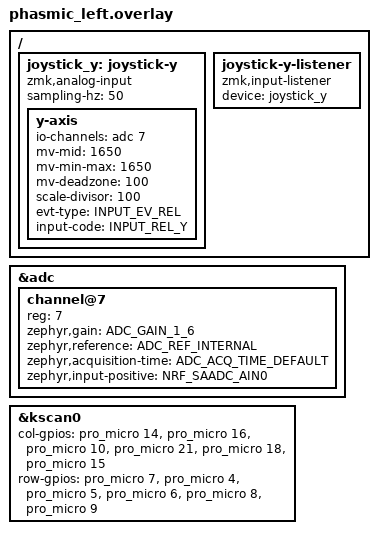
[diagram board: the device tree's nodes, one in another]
/*
 * Copyright (c) 2020 Ryan Cross
 *
 * SPDX-License-Identifier: MIT
 */

#include <zephyr/dt-bindings/adc/adc.h>
#include <zephyr/dt-bindings/adc/nrf-adc.h>
#include <zephyr/dt-bindings/input/input-event-codes.h>
#include "phasmic.dtsi"

&adc {
    #address-cells = <1>;
    #size-cells = <0>;

    channel@7 {
        // D19 (P0.02 / AIN0). ADC channel 0 is used for battery sensing.
        reg = <7>;
        zephyr,gain = "ADC_GAIN_1_6";
        zephyr,reference = "ADC_REF_INTERNAL";
        zephyr,acquisition-time = <ADC_ACQ_TIME_DEFAULT>;
        zephyr,input-positive = <NRF_SAADC_AIN0>;
    };
};

/ {
    joystick_y: joystick-y {
        compatible = "zmk,analog-input";
        sampling-hz = <50>;

        y-axis {
            io-channels = <&adc 7>;
            // Replace with the measured resting voltage if the cursor drifts.
            mv-mid = <1650>;
            mv-min-max = <1650>;
            mv-deadzone = <100>;
            scale-divisor = <100>;
            evt-type = <INPUT_EV_REL>;
            input-code = <INPUT_REL_Y>;
        };
    };

    joystick-y-listener {
        compatible = "zmk,input-listener";
        device = <&joystick_y>;
    };
};

&kscan0 {
    col-gpios
        = <&pro_micro 14 (GPIO_ACTIVE_HIGH)>
        , <&pro_micro 16 (GPIO_ACTIVE_HIGH)>
        , <&pro_micro 10 (GPIO_ACTIVE_HIGH)>
        , <&pro_micro 21 (GPIO_ACTIVE_HIGH)> // Unwired placeholder preserves column indices.
        , <&pro_micro 18 (GPIO_ACTIVE_HIGH)>
        , <&pro_micro 15 (GPIO_ACTIVE_HIGH)>
        ;

    row-gpios

        = <&pro_micro 7 (GPIO_ACTIVE_HIGH | GPIO_PULL_DOWN)>
        , <&pro_micro 4 (GPIO_ACTIVE_HIGH | GPIO_PULL_DOWN)>
        , <&pro_micro 5 (GPIO_ACTIVE_HIGH | GPIO_PULL_DOWN)>
        , <&pro_micro 6 (GPIO_ACTIVE_HIGH | GPIO_PULL_DOWN)>
        , <&pro_micro 8 (GPIO_ACTIVE_HIGH | GPIO_PULL_DOWN)>
        , <&pro_micro 9 (GPIO_ACTIVE_HIGH | GPIO_PULL_DOWN)>
        ;
};
